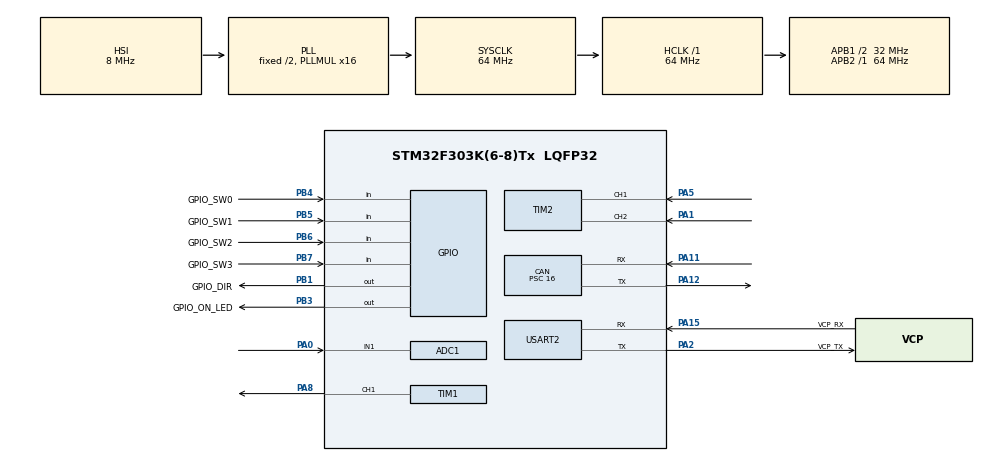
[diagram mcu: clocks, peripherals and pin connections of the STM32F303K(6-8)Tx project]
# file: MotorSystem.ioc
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ADC1.Channel-1\#ChannelRegularConversion=ADC_CHANNEL_1
ADC1.ContinuousConvMode=ENABLE
ADC1.ExternalTrigConv=ADC_SOFTWARE_START
ADC1.NbrOfConversion=1
ADC1.NbrOfConversionFlag=1
ADC1.Offset-1\#ChannelRegularConversion=0
ADC1.OffsetNumber-1\#ChannelRegularConversion=ADC_OFFSET_NONE
ADC1.Rank-1\#ChannelRegularConversion=1
ADC1.SamplingTime-1\#ChannelRegularConversion=ADC_SAMPLETIME_1CYCLE_5
ADC1.SubFamily=STM32F303x8
ADC1.master=1
CAN.AWUM=ENABLE
CAN.BS1=CAN_BS1_2TQ
CAN.CalculateTimeQuantum=500.0
CAN.Mode=CAN_MODE_NORMAL
CAN.Prescaler=16
CAN.SJW=CAN_SJW_1TQ
CAN.TXFP=ENABLE
Dma.Request0=USART2_TX
Dma.Request1=USART2_RX
Dma.USART2_RX.1.Direction=DMA_PERIPH_TO_MEMORY
Dma.USART2_RX.1.Instance=DMA1_Channel6
Dma.USART2_RX.1.MemDataAlignment=DMA_MDATAALIGN_BYTE
Dma.USART2_RX.1.MemInc=DMA_MINC_ENABLE
Dma.USART2_RX.1.Mode=DMA_CIRCULAR
Dma.USART2_RX.1.PeriphDataAlignment=DMA_PDATAALIGN_BYTE
Dma.USART2_RX.1.PeriphInc=DMA_PINC_DISABLE
Dma.USART2_RX.1.Priority=DMA_PRIORITY_LOW
Dma.USART2_TX.0.Direction=DMA_MEMORY_TO_PERIPH
Dma.USART2_TX.0.Instance=DMA1_Channel7
Dma.USART2_TX.0.MemDataAlignment=DMA_MDATAALIGN_BYTE
Dma.USART2_TX.0.MemInc=DMA_MINC_ENABLE
Dma.USART2_TX.0.Mode=DMA_CIRCULAR
Dma.USART2_TX.0.PeriphDataAlignment=DMA_PDATAALIGN_BYTE
Dma.USART2_TX.0.PeriphInc=DMA_PINC_DISABLE
Dma.USART2_TX.0.Priority=DMA_PRIORITY_LOW
Mcu.Family=STM32F3
Mcu.Name=STM32F303K(6-8)Tx
Mcu.Package=LQFP32
NVIC.CAN_RX0_IRQn=true\:1\:0\:true\:false\:true\:true\:true
NVIC.CAN_RX1_IRQn=true\:1\:0\:true\:false\:true\:true\:true
NVIC.DMA1_Channel6_IRQn=true\:0\:0\:false\:false\:true\:false\:true
NVIC.DMA1_Channel7_IRQn=true\:0\:0\:false\:false\:true\:false\:true
NVIC.PriorityGroup=NVIC_PRIORITYGROUP_4
NVIC.TIM1_BRK_TIM15_IRQn=true\:0\:0\:false\:false\:true\:true\:true
NVIC.TIM1_TRG_COM_TIM17_IRQn=true\:1\:0\:true\:false\:true\:true\:true
PA0.Mode=IN1-Single-Ended
PA0.Signal=ADC1_IN1
PA1.Signal=S_TIM2_CH2
PA11.Mode=Master
PA11.Signal=CAN_RX
PA12.Mode=Master
PA12.Signal=CAN_TX
PA13.GPIO_Label=SWDIO
PA13.Mode=Serial_Wire
PA13.Signal=SYS_JTMS-SWDIO
PA14.GPIO_Label=SWCLK
PA14.Mode=Serial_Wire
PA14.Signal=SYS_JTCK-SWCLK
PA15.GPIO_Label=VCP_RX
PA15.Mode=Asynchronous
PA15.Signal=USART2_RX
PA2.GPIO_Label=VCP_TX
PA2.Mode=Asynchronous
PA2.Signal=USART2_TX
PA5.Signal=S_TIM2_CH1_ETR
PA8.Signal=S_TIM1_CH1
PB1.GPIO_Label=GPIO_DIR
PB1.Signal=GPIO_Output
PB3.GPIO_Label=GPIO_ON_LED
PB3.Signal=GPIO_Output
PB4.GPIO_Label=GPIO_SW0
PB4.GPIO_PuPd=GPIO_PULLUP
PB4.Signal=GPIO_Input
PB5.GPIO_Label=GPIO_SW1
PB5.GPIO_PuPd=GPIO_PULLUP
PB5.Signal=GPIO_Input
PB6.GPIO_Label=GPIO_SW2
PB6.GPIO_PuPd=GPIO_PULLUP
PB6.Signal=GPIO_Input
PB7.GPIO_Label=GPIO_SW3
PB7.GPIO_PuPd=GPIO_PULLUP
PB7.Signal=GPIO_Input
PF0\ /\ OSC_IN.GPIO_Label=MCO
PF0\ /\ OSC_IN.Mode=HSE-External-Clock-Source
PF0\ /\ OSC_IN.Signal=RCC_OSC_IN
ProjectManager.HeapSize=0x200
ProjectManager.StackSize=0x400
ProjectManager.TargetToolchain=STM32CubeIDE
RCC.AHBFreq_Value=64000000
RCC.APB1CLKDivider=RCC_HCLK_DIV2
RCC.APB1Freq_Value=32000000
RCC.APB1TimFreq_Value=64000000
RCC.APB2Freq_Value=64000000
RCC.APB2TimFreq_Value=64000000
RCC.CortexFreq_Value=64000000
RCC.HCLKFreq_Value=64000000
RCC.HSE_VALUE=8000000
RCC.HSI_VALUE=8000000
RCC.PLLMUL=RCC_PLL_MUL16
RCC.SYSCLKFreq_VALUE=64000000
RCC.SYSCLKSourceVirtual=RCC_SYSCLKSOURCE_PLLCLK
SH.S_TIM1_CH1.0=TIM1_CH1,PWM Generation1 CH1
SH.S_TIM2_CH1_ETR.0=TIM2_CH1,Encoder_Interface
SH.S_TIM2_CH2.0=TIM2_CH2,Encoder_Interface
TIM1.Channel-PWM\ Generation1\ CH1=TIM_CHANNEL_1
TIM1.Period=2133
TIM1.Prescaler=0
TIM15.AutoReloadPreload=TIM_AUTORELOAD_PRELOAD_ENABLE
TIM15.Channel-Input_Capture1_from_TRC=TIM_CHANNEL_1
TIM15.Prescaler=2
TIM15.TIM_MasterOutputTrigger=TIM_TRGO_OC1
TIM15.TIM_MasterSlaveMode=TIM_MASTERSLAVEMODE_DISABLE
TIM16.Channel=TIM_CHANNEL_1
TIM17.AutoReloadPreload=TIM_AUTORELOAD_PRELOAD_ENABLE
TIM17.Period=20000
TIM17.Prescaler=32
TIM2.EncoderMode=TIM_ENCODERMODE_TI12
TIM2.TIM_MasterOutputTrigger=TIM_TRGO_RESET
TIM2.TIM_MasterSlaveMode=TIM_MASTERSLAVEMODE_DISABLE
USART2.VirtualMode-Asynchronous=VM_ASYNC
VP_TIM15_VS_CH1.Mode=Input_Capture1_from_TRC
VP_TIM15_VS_ClockSourceITR.Mode=TriggerSource_ITR3
VP_TIM15_VS_ControllerModeReset.Mode=Reset Mode
VP_TIM16_VS_ClockSourceINT.Mode=Enable_Timer
VP_TIM16_VS_no_output1.Mode=Output Compare1 No Output
VP_TIM17_VS_ClockSourceINT.Mode=Enable_Timer
VP_TIM1_VS_ClockSourceINT.Mode=Internal
board=NUCLEO-F303K8

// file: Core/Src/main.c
/* USER CODE BEGIN Header */
/**
  ******************************************************************************
  * @file           : main.c
  * @brief          : Main program body
  ******************************************************************************
  * @attention
  *
  * <h2><center>&copy; Copyright (c) 2020 STMicroelectronics.
  * All rights reserved.</center></h2>
  *
  * This software component is licensed by ST under BSD 3-Clause license,
  * the "License"; You may not use this file except in compliance with the
  * License. You may obtain a copy of the License at:
  *                        opensource.org/licenses/BSD-3-Clause
  *
  ******************************************************************************
  */
/* USER CODE END Header */
#include "main.h"

/* USER CODE BEGIN Includes */
#include<stdio.h>
#include<math.h>
#include"cppmain.hpp"
/* USER CODE END Includes */

ADC_HandleTypeDef hadc1;

CAN_HandleTypeDef hcan;

TIM_HandleTypeDef htim1;
TIM_HandleTypeDef htim2;
TIM_HandleTypeDef htim15;
TIM_HandleTypeDef htim16;
TIM_HandleTypeDef htim17;

UART_HandleTypeDef huart2;
DMA_HandleTypeDef hdma_usart2_tx;
DMA_HandleTypeDef hdma_usart2_rx;

void SystemClock_Config(void);
static void MX_GPIO_Init(void);
static void MX_DMA_Init(void);
static void MX_USART2_UART_Init(void);
static void MX_CAN_Init(void);
static void MX_TIM1_Init(void);
static void MX_TIM2_Init(void);
static void MX_ADC1_Init(void);
static void MX_TIM17_Init(void);
static void MX_TIM15_Init(void);
static void MX_TIM16_Init(void);

int main(void)
{

  /* MCU Configuration--------------------------------------------------------*/

  /* Reset of all peripherals, Initializes the Flash interface and the Systick. */
  HAL_Init();

  /* Configure the system clock */
  SystemClock_Config();

  /* Initialize all configured peripherals */
  MX_GPIO_Init();
  MX_DMA_Init();
  MX_USART2_UART_Init();
  MX_CAN_Init();
  MX_TIM1_Init();
  MX_TIM2_Init();
  MX_ADC1_Init();
  MX_TIM17_Init();
  MX_TIM15_Init();
  MX_TIM16_Init();
  /* USER CODE BEGIN 2 */
  cpp_Init();

  /* USER CODE END 2 */

  /* Infinite loop */
  /* USER CODE BEGIN WHILE */
  cpp_MainLoop();
  while (1)
  {
    /* USER CODE END WHILE */

  }
}

void SystemClock_Config(void)
{
  RCC_OscInitTypeDef RCC_OscInitStruct = {0};
  RCC_ClkInitTypeDef RCC_ClkInitStruct = {0};
  RCC_PeriphCLKInitTypeDef PeriphClkInit = {0};

  /** Initializes the RCC Oscillators according to the specified parameters
  * in the RCC_OscInitTypeDef structure.
  */
  RCC_OscInitStruct.OscillatorType = RCC_OSCILLATORTYPE_HSI;
  RCC_OscInitStruct.HSIState = RCC_HSI_ON;
  RCC_OscInitStruct.HSICalibrationValue = RCC_HSICALIBRATION_DEFAULT;
  RCC_OscInitStruct.PLL.PLLState = RCC_PLL_ON;
  RCC_OscInitStruct.PLL.PLLSource = RCC_PLLSOURCE_HSI;
  RCC_OscInitStruct.PLL.PLLMUL = RCC_PLL_MUL16;
  if (HAL_RCC_OscConfig(&RCC_OscInitStruct) != HAL_OK)
  {
    Error_Handler();
  }
  /** Initializes the CPU, AHB and APB buses clocks
  */
  RCC_ClkInitStruct.ClockType = RCC_CLOCKTYPE_HCLK|RCC_CLOCKTYPE_SYSCLK
                              |RCC_CLOCKTYPE_PCLK1|RCC_CLOCKTYPE_PCLK2;
  RCC_ClkInitStruct.SYSCLKSource = RCC_SYSCLKSOURCE_PLLCLK;
  RCC_ClkInitStruct.AHBCLKDivider = RCC_SYSCLK_DIV1;
  RCC_ClkInitStruct.APB1CLKDivider = RCC_HCLK_DIV2;
  RCC_ClkInitStruct.APB2CLKDivider = RCC_HCLK_DIV1;

  if (HAL_RCC_ClockConfig(&RCC_ClkInitStruct, FLASH_LATENCY_2) != HAL_OK)
  {
    Error_Handler();
  }
  PeriphClkInit.PeriphClockSelection = RCC_PERIPHCLK_TIM1|RCC_PERIPHCLK_ADC12;
  PeriphClkInit.Adc12ClockSelection = RCC_ADC12PLLCLK_DIV1;
  PeriphClkInit.Tim1ClockSelection = RCC_TIM1CLK_HCLK;
  if (HAL_RCCEx_PeriphCLKConfig(&PeriphClkInit) != HAL_OK)
  {
    Error_Handler();
  }
}

static void MX_ADC1_Init(void)
{

  ADC_MultiModeTypeDef multimode = {0};
  ADC_ChannelConfTypeDef sConfig = {0};

  /** Common config
  */
  hadc1.Instance = ADC1;
  hadc1.Init.ClockPrescaler = ADC_CLOCK_ASYNC_DIV1;
  hadc1.Init.Resolution = ADC_RESOLUTION_12B;
  hadc1.Init.ScanConvMode = ADC_SCAN_DISABLE;
  hadc1.Init.ContinuousConvMode = ENABLE;
  hadc1.Init.DiscontinuousConvMode = DISABLE;
  hadc1.Init.ExternalTrigConvEdge = ADC_EXTERNALTRIGCONVEDGE_NONE;
  hadc1.Init.ExternalTrigConv = ADC_SOFTWARE_START;
  hadc1.Init.DataAlign = ADC_DATAALIGN_RIGHT;
  hadc1.Init.NbrOfConversion = 1;
  hadc1.Init.DMAContinuousRequests = DISABLE;
  hadc1.Init.EOCSelection = ADC_EOC_SINGLE_CONV;
  hadc1.Init.LowPowerAutoWait = DISABLE;
  hadc1.Init.Overrun = ADC_OVR_DATA_OVERWRITTEN;
  if (HAL_ADC_Init(&hadc1) != HAL_OK)
  {
    Error_Handler();
  }
  /** Configure the ADC multi-mode
  */
  multimode.Mode = ADC_MODE_INDEPENDENT;
  if (HAL_ADCEx_MultiModeConfigChannel(&hadc1, &multimode) != HAL_OK)
  {
    Error_Handler();
  }
  /** Configure Regular Channel
  */
  sConfig.Channel = ADC_CHANNEL_1;
  sConfig.Rank = ADC_REGULAR_RANK_1;
  sConfig.SingleDiff = ADC_SINGLE_ENDED;
  sConfig.SamplingTime = ADC_SAMPLETIME_1CYCLE_5;
  sConfig.OffsetNumber = ADC_OFFSET_NONE;
  sConfig.Offset = 0;
  if (HAL_ADC_ConfigChannel(&hadc1, &sConfig) != HAL_OK)
  {
    Error_Handler();
  }

}

static void MX_CAN_Init(void)
{

  hcan.Instance = CAN;
  hcan.Init.Prescaler = 16;
  hcan.Init.Mode = CAN_MODE_NORMAL;
  hcan.Init.SyncJumpWidth = CAN_SJW_1TQ;
  hcan.Init.TimeSeg1 = CAN_BS1_2TQ;
  hcan.Init.TimeSeg2 = CAN_BS2_1TQ;
  hcan.Init.TimeTriggeredMode = DISABLE;
  hcan.Init.AutoBusOff = DISABLE;
  hcan.Init.AutoWakeUp = ENABLE;
  hcan.Init.AutoRetransmission = DISABLE;
  hcan.Init.ReceiveFifoLocked = DISABLE;
  hcan.Init.TransmitFifoPriority = ENABLE;
  if (HAL_CAN_Init(&hcan) != HAL_OK)
  {
    Error_Handler();
  }

}

static void MX_TIM1_Init(void)
{

  TIM_ClockConfigTypeDef sClockSourceConfig = {0};
  TIM_MasterConfigTypeDef sMasterConfig = {0};
  TIM_OC_InitTypeDef sConfigOC = {0};
  TIM_BreakDeadTimeConfigTypeDef sBreakDeadTimeConfig = {0};

  htim1.Instance = TIM1;
  htim1.Init.Prescaler = 0;
  htim1.Init.CounterMode = TIM_COUNTERMODE_UP;
  htim1.Init.Period = 2133;
  htim1.Init.ClockDivision = TIM_CLOCKDIVISION_DIV1;
  htim1.Init.RepetitionCounter = 0;
  htim1.Init.AutoReloadPreload = TIM_AUTORELOAD_PRELOAD_DISABLE;
  if (HAL_TIM_Base_Init(&htim1) != HAL_OK)
  {
    Error_Handler();
  }
  sClockSourceConfig.ClockSource = TIM_CLOCKSOURCE_INTERNAL;
  if (HAL_TIM_ConfigClockSource(&htim1, &sClockSourceConfig) != HAL_OK)
  {
    Error_Handler();
  }
  if (HAL_TIM_PWM_Init(&htim1) != HAL_OK)
  {
    Error_Handler();
  }
  sMasterConfig.MasterOutputTrigger = TIM_TRGO_RESET;
  sMasterConfig.MasterOutputTrigger2 = TIM_TRGO2_RESET;
  sMasterConfig.MasterSlaveMode = TIM_MASTERSLAVEMODE_DISABLE;
  if (HAL_TIMEx_MasterConfigSynchronization(&htim1, &sMasterConfig) != HAL_OK)
  {
    Error_Handler();
  }
  sConfigOC.OCMode = TIM_OCMODE_PWM1;
  sConfigOC.Pulse = 0;
  sConfigOC.OCPolarity = TIM_OCPOLARITY_HIGH;
  sConfigOC.OCNPolarity = TIM_OCNPOLARITY_HIGH;
  sConfigOC.OCFastMode = TIM_OCFAST_DISABLE;
  sConfigOC.OCIdleState = TIM_OCIDLESTATE_RESET;
  sConfigOC.OCNIdleState = TIM_OCNIDLESTATE_RESET;
  if (HAL_TIM_PWM_ConfigChannel(&htim1, &sConfigOC, TIM_CHANNEL_1) != HAL_OK)
  {
    Error_Handler();
  }
  sBreakDeadTimeConfig.OffStateRunMode = TIM_OSSR_DISABLE;
  sBreakDeadTimeConfig.OffStateIDLEMode = TIM_OSSI_DISABLE;
  sBreakDeadTimeConfig.LockLevel = TIM_LOCKLEVEL_OFF;
  sBreakDeadTimeConfig.DeadTime = 0;
  sBreakDeadTimeConfig.BreakState = TIM_BREAK_DISABLE;
  sBreakDeadTimeConfig.BreakPolarity = TIM_BREAKPOLARITY_HIGH;
  sBreakDeadTimeConfig.BreakFilter = 0;
  sBreakDeadTimeConfig.Break2State = TIM_BREAK2_DISABLE;
  sBreakDeadTimeConfig.Break2Polarity = TIM_BREAK2POLARITY_HIGH;
  sBreakDeadTimeConfig.Break2Filter = 0;
  sBreakDeadTimeConfig.AutomaticOutput = TIM_AUTOMATICOUTPUT_DISABLE;
  if (HAL_TIMEx_ConfigBreakDeadTime(&htim1, &sBreakDeadTimeConfig) != HAL_OK)
  {
    Error_Handler();
  }
  HAL_TIM_MspPostInit(&htim1);

}

static void MX_TIM2_Init(void)
{

  TIM_Encoder_InitTypeDef sConfig = {0};
  TIM_MasterConfigTypeDef sMasterConfig = {0};

  htim2.Instance = TIM2;
  htim2.Init.Prescaler = 0;
  htim2.Init.CounterMode = TIM_COUNTERMODE_UP;
  htim2.Init.Period = 4294967295;
  htim2.Init.ClockDivision = TIM_CLOCKDIVISION_DIV1;
  htim2.Init.AutoReloadPreload = TIM_AUTORELOAD_PRELOAD_DISABLE;
  sConfig.EncoderMode = TIM_ENCODERMODE_TI12;
  sConfig.IC1Polarity = TIM_ICPOLARITY_RISING;
  sConfig.IC1Selection = TIM_ICSELECTION_DIRECTTI;
  sConfig.IC1Prescaler = TIM_ICPSC_DIV1;
  sConfig.IC1Filter = 0;
  sConfig.IC2Polarity = TIM_ICPOLARITY_RISING;
  sConfig.IC2Selection = TIM_ICSELECTION_DIRECTTI;
  sConfig.IC2Prescaler = TIM_ICPSC_DIV1;
  sConfig.IC2Filter = 0;
  if (HAL_TIM_Encoder_Init(&htim2, &sConfig) != HAL_OK)
  {
    Error_Handler();
  }
  sMasterConfig.MasterOutputTrigger = TIM_TRGO_RESET;
  sMasterConfig.MasterSlaveMode = TIM_MASTERSLAVEMODE_DISABLE;
  if (HAL_TIMEx_MasterConfigSynchronization(&htim2, &sMasterConfig) != HAL_OK)
  {
    Error_Handler();
  }

}

static void MX_TIM15_Init(void)
{

  TIM_SlaveConfigTypeDef sSlaveConfig = {0};
  TIM_MasterConfigTypeDef sMasterConfig = {0};
  TIM_IC_InitTypeDef sConfigIC = {0};

  htim15.Instance = TIM15;
  htim15.Init.Prescaler = 2;
  htim15.Init.CounterMode = TIM_COUNTERMODE_UP;
  htim15.Init.Period = 65535;
  htim15.Init.ClockDivision = TIM_CLOCKDIVISION_DIV1;
  htim15.Init.RepetitionCounter = 0;
  htim15.Init.AutoReloadPreload = TIM_AUTORELOAD_PRELOAD_ENABLE;
  if (HAL_TIM_Base_Init(&htim15) != HAL_OK)
  {
    Error_Handler();
  }
  if (HAL_TIM_IC_Init(&htim15) != HAL_OK)
  {
    Error_Handler();
  }
  sSlaveConfig.SlaveMode = TIM_SLAVEMODE_RESET;
  sSlaveConfig.InputTrigger = TIM_TS_ITR3;
  if (HAL_TIM_SlaveConfigSynchro(&htim15, &sSlaveConfig) != HAL_OK)
  {
    Error_Handler();
  }
  sMasterConfig.MasterOutputTrigger = TIM_TRGO_OC1;
  sMasterConfig.MasterSlaveMode = TIM_MASTERSLAVEMODE_DISABLE;
  if (HAL_TIMEx_MasterConfigSynchronization(&htim15, &sMasterConfig) != HAL_OK)
  {
    Error_Handler();
  }
  sConfigIC.ICPolarity = TIM_INPUTCHANNELPOLARITY_RISING;
  sConfigIC.ICSelection = TIM_ICSELECTION_TRC;
  sConfigIC.ICPrescaler = TIM_ICPSC_DIV1;
  sConfigIC.ICFilter = 0;
  if (HAL_TIM_IC_ConfigChannel(&htim15, &sConfigIC, TIM_CHANNEL_1) != HAL_OK)
  {
    Error_Handler();
  }

}

static void MX_TIM16_Init(void)
{

  TIM_OC_InitTypeDef sConfigOC = {0};
  TIM_BreakDeadTimeConfigTypeDef sBreakDeadTimeConfig = {0};

  htim16.Instance = TIM16;
  htim16.Init.Prescaler = 0;
  htim16.Init.CounterMode = TIM_COUNTERMODE_UP;
  htim16.Init.Period = 65535;
  htim16.Init.ClockDivision = TIM_CLOCKDIVISION_DIV1;
  htim16.Init.RepetitionCounter = 0;
  htim16.Init.AutoReloadPreload = TIM_AUTORELOAD_PRELOAD_DISABLE;
  if (HAL_TIM_Base_Init(&htim16) != HAL_OK)
  {
    Error_Handler();
  }
  if (HAL_TIM_OC_Init(&htim16) != HAL_OK)
  {
    Error_Handler();
  }
  sConfigOC.OCMode = TIM_OCMODE_TIMING;
  sConfigOC.Pulse = 0;
  sConfigOC.OCPolarity = TIM_OCPOLARITY_HIGH;
  sConfigOC.OCNPolarity = TIM_OCNPOLARITY_HIGH;
  sConfigOC.OCFastMode = TIM_OCFAST_DISABLE;
  sConfigOC.OCIdleState = TIM_OCIDLESTATE_RESET;
  sConfigOC.OCNIdleState = TIM_OCNIDLESTATE_RESET;
  if (HAL_TIM_OC_ConfigChannel(&htim16, &sConfigOC, TIM_CHANNEL_1) != HAL_OK)
  {
    Error_Handler();
  }
  sBreakDeadTimeConfig.OffStateRunMode = TIM_OSSR_DISABLE;
  sBreakDeadTimeConfig.OffStateIDLEMode = TIM_OSSI_DISABLE;
  sBreakDeadTimeConfig.LockLevel = TIM_LOCKLEVEL_OFF;
  sBreakDeadTimeConfig.DeadTime = 0;
  sBreakDeadTimeConfig.BreakState = TIM_BREAK_DISABLE;
  sBreakDeadTimeConfig.BreakPolarity = TIM_BREAKPOLARITY_HIGH;
  sBreakDeadTimeConfig.BreakFilter = 0;
  sBreakDeadTimeConfig.AutomaticOutput = TIM_AUTOMATICOUTPUT_DISABLE;
  if (HAL_TIMEx_ConfigBreakDeadTime(&htim16, &sBreakDeadTimeConfig) != HAL_OK)
  {
    Error_Handler();
  }

}

static void MX_TIM17_Init(void)
{

  htim17.Instance = TIM17;
  htim17.Init.Prescaler = 32;
  htim17.Init.CounterMode = TIM_COUNTERMODE_UP;
  htim17.Init.Period = 20000;
  htim17.Init.ClockDivision = TIM_CLOCKDIVISION_DIV1;
  htim17.Init.RepetitionCounter = 0;
  htim17.Init.AutoReloadPreload = TIM_AUTORELOAD_PRELOAD_ENABLE;
  if (HAL_TIM_Base_Init(&htim17) != HAL_OK)
  {
    Error_Handler();
  }

}

static void MX_USART2_UART_Init(void)
{

  huart2.Instance = USART2;
  huart2.Init.BaudRate = 38400;
  huart2.Init.WordLength = UART_WORDLENGTH_8B;
  huart2.Init.StopBits = UART_STOPBITS_1;
  huart2.Init.Parity = UART_PARITY_NONE;
  huart2.Init.Mode = UART_MODE_TX_RX;
  huart2.Init.HwFlowCtl = UART_HWCONTROL_NONE;
  huart2.Init.OverSampling = UART_OVERSAMPLING_16;
  huart2.Init.OneBitSampling = UART_ONE_BIT_SAMPLE_DISABLE;
  huart2.AdvancedInit.AdvFeatureInit = UART_ADVFEATURE_NO_INIT;
  if (HAL_UART_Init(&huart2) != HAL_OK)
  {
    Error_Handler();
  }

}

static void MX_DMA_Init(void)
{

  /* DMA controller clock enable */
  __HAL_RCC_DMA1_CLK_ENABLE();

  /* DMA interrupt init */
  /* DMA1_Channel6_IRQn interrupt configuration */
  HAL_NVIC_SetPriority(DMA1_Channel6_IRQn, 0, 0);
  HAL_NVIC_EnableIRQ(DMA1_Channel6_IRQn);
  /* DMA1_Channel7_IRQn interrupt configuration */
  HAL_NVIC_SetPriority(DMA1_Channel7_IRQn, 0, 0);
  HAL_NVIC_EnableIRQ(DMA1_Channel7_IRQn);

}

static void MX_GPIO_Init(void)
{
  GPIO_InitTypeDef GPIO_InitStruct = {0};

  /* GPIO Ports Clock Enable */
  __HAL_RCC_GPIOF_CLK_ENABLE();
  __HAL_RCC_GPIOA_CLK_ENABLE();
  __HAL_RCC_GPIOB_CLK_ENABLE();

  /*Configure GPIO pin Output Level */
  HAL_GPIO_WritePin(GPIOB, GPIO_DIR_Pin|GPIO_ON_LED_Pin, GPIO_PIN_RESET);

  /*Configure GPIO pins : GPIO_DIR_Pin GPIO_ON_LED_Pin */
  GPIO_InitStruct.Pin = GPIO_DIR_Pin|GPIO_ON_LED_Pin;
  GPIO_InitStruct.Mode = GPIO_MODE_OUTPUT_PP;
  GPIO_InitStruct.Pull = GPIO_NOPULL;
  GPIO_InitStruct.Speed = GPIO_SPEED_FREQ_LOW;
  HAL_GPIO_Init(GPIOB, &GPIO_InitStruct);

  /*Configure GPIO pins : GPIO_SW0_Pin GPIO_SW1_Pin GPIO_SW2_Pin GPIO_SW3_Pin */
  GPIO_InitStruct.Pin = GPIO_SW0_Pin|GPIO_SW1_Pin|GPIO_SW2_Pin|GPIO_SW3_Pin;
  GPIO_InitStruct.Mode = GPIO_MODE_INPUT;
  GPIO_InitStruct.Pull = GPIO_PULLUP;
  HAL_GPIO_Init(GPIOB, &GPIO_InitStruct);

}

void Error_Handler(void)
{
  /* USER CODE BEGIN Error_Handler_Debug */
  /* User can add his own implementation to report the HAL error return state */
	//printf("Error Handler\r\n");
	while(1);

  /* USER CODE END Error_Handler_Debug */
}

/************************ (C) COPYRIGHT STMicroelectronics *****END OF FILE****/
